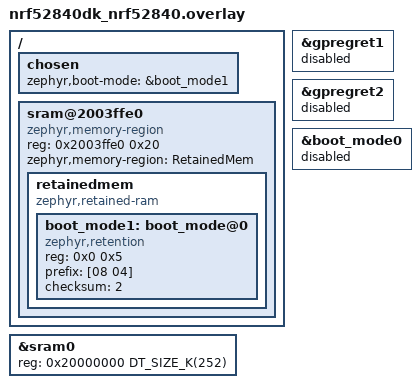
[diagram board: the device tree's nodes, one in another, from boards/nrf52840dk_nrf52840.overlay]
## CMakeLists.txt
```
#
# Copyright (c) 2026 Nordic Semiconductor ASA
#
# SPDX-License-Identifier: Apache-2.0
#

cmake_minimum_required(VERSION 3.28.0)
find_package(Zephyr REQUIRED HINTS $ENV{ZEPHYR_BASE})
project(retention_bootmode)

target_sources(app PRIVATE src/main.c)
```

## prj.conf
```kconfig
CONFIG_RETAINED_MEM=y
CONFIG_RETENTION=y
CONFIG_BOOT_MODE=y
CONFIG_ZTEST=y
CONFIG_REBOOT=y
```

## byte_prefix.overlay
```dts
/*
 * SPDX-FileCopyrightText: Copyright The Zephyr Project Contributors
 * SPDX-License-Identifier: Apache-2.0
 */

/* Boot mode byte behind a 4-byte prefix */
&boot_mode {
	reg = <0x0 0x5>;
	prefix = [ef 69 16 f0];
};
```

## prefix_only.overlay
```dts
/*
 * SPDX-FileCopyrightText: Copyright The Zephyr Project Contributors
 * SPDX-License-Identifier: Apache-2.0
 */

/* Prefix only, no boot mode byte: the prefix is a bootloader magic value */
&boot_mode {
	reg = <0x0 0x4>;
	prefix = [ef 69 16 f0];
};
```

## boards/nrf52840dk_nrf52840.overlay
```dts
/*
 * Copyright (c) 2026 The Zephyr Project Contributors
 *
 * SPDX-License-Identifier: Apache-2.0
 */

/ {
	chosen {
		zephyr,boot-mode = &boot_mode1;
	};

	sram@2003ffe0 {
		compatible = "zephyr,memory-region", "mmio-sram";
		reg = <0x2003ffe0 0x20>;
		ranges = <0x0 0x2003ffe0 0x20>;
		#address-cells = <1>;
		#size-cells = <1>;
		zephyr,memory-region = "RetainedMem";
		status = "okay";

		retainedmem {
			compatible = "zephyr,retained-ram";
			ranges;
			#address-cells = <1>;
			#size-cells = <1>;
			status = "okay";

			boot_mode1: boot_mode@0 {
				compatible = "zephyr,retention";
				reg = <0x0 0x5>;
				prefix = [08 04];
				checksum = <2>;
				status = "okay";
			};
		};
	};
};

&gpregret1 {
	status = "disabled";
};

&gpregret2 {
	status = "disabled";
};

&sram0 {
	reg = <0x20000000 DT_SIZE_K(252)>;
};

&boot_mode0 {
	status = "disabled";
};
```

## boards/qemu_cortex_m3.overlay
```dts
/*
 * Copyright (c) 2026 The Zephyr Project Contributors
 *
 * SPDX-License-Identifier: Apache-2.0
 */

#include <common/mem.h>

/ {
	chosen {
		zephyr,boot-mode = &boot_mode0;
	};

	sram@2000ffe0 {
		compatible = "zephyr,memory-region", "mmio-sram";
		reg = <0x2000ffe0 0x20>;
		ranges = <0x0 0x2000ffe0 0x20>;
		#address-cells = <1>;
		#size-cells = <1>;
		zephyr,memory-region = "Retention";
		status = "okay";

		retainedmem0: retainedmem {
			compatible = "zephyr,retained-ram";
			ranges;
			#address-cells = <1>;
			#size-cells = <1>;
			status = "okay";

			boot_mode0: boot_mode@0 {
				compatible = "zephyr,retention";
				reg = <0x0 0x5>;
				prefix = [08 04];
				checksum = <2>;
				status = "okay";
			};
		};
	};
};

&sram0 {
	reg = <0x20000000 DT_SIZE_K(60)>;
};
```

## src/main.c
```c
/*
 * Copyright (c) 2026, Nordic Semiconductor ASA
 *
 * SPDX-License-Identifier: Apache-2.0
 */
#include <zephyr/cache.h>
#include <zephyr/drivers/retained_mem.h>
#include <zephyr/bootmode.h>
#include <zephyr/ztest.h>
#include <errno.h>
#include <zephyr/sys/reboot.h>

const static struct device *retained_memory_device = DEVICE_DT_GET(DT_PARENT(DT_CHOSEN(
									zephyr_boot_mode)));

#define TEST_STATUS_NORMAL 0x0
#define TEST_STATUS_REBOOT1 0x184be001
#define TEST_STATUS_REBOOT2 0x391b
#define BOOTMODE_NORMAL 0x0
#define BOOTMODE_VALUE1 0x14
#define BOOTMODE_VALUE2 0xf1
volatile uint32_t test_status __attribute__((section(".noinit.test")));

ZTEST(retention_bootmode_reboot, test_bootmode)
{
	int32_t rc;

	if (test_status == TEST_STATUS_REBOOT1) {
		test_status = BOOTMODE_VALUE2;
		sys_cache_data_flush_range((void *)(uintptr_t)&test_status, sizeof(test_status));

		rc = bootmode_check(BOOTMODE_VALUE1);
		zassert_equal(rc, 1, "Boot mode should be set to test value 1: %d", rc);

		rc = bootmode_check(BOOTMODE_VALUE2);
		zassert_equal(rc, 0, "Boot mode should not be set to test value 2: %d", rc);

		rc = bootmode_check(BOOTMODE_NORMAL);
		zassert_equal(rc, 0, "Boot mode should not be set to default value: %d", rc);

		rc = bootmode_set(BOOTMODE_VALUE2);
		zassert_equal(rc, 0, "Boot mode set should work: %d", rc);

		test_status = TEST_STATUS_REBOOT2;
		sys_cache_data_flush_range((void *)(uintptr_t)&test_status, sizeof(test_status));

		sys_reboot(SYS_REBOOT_COLD);
	} else if (test_status == TEST_STATUS_REBOOT2) {
		test_status = BOOTMODE_NORMAL;
		sys_cache_data_flush_range((void *)(uintptr_t)&test_status, sizeof(test_status));

		rc = bootmode_check(BOOTMODE_VALUE1);
		zassert_equal(rc, 0, "Boot mode should not be set to test value 1: %d", rc);

		rc = bootmode_check(BOOTMODE_VALUE2);
		zassert_equal(rc, 1, "Boot mode should be set to test value 2: %d", rc);

		rc = bootmode_check(BOOTMODE_NORMAL);
		zassert_equal(rc, 0, "Boot mode should not be set to default value: %d", rc);

		/*
		 * Use retained memory directly to ensure checksum and prefix is cleared after test
		 */
		rc = retained_mem_clear(retained_memory_device);
		zassert_equal(rc, 0, "Return code should be success: %d", rc);
	} else {
		rc = bootmode_check(BOOTMODE_VALUE1);
		zassert_equal(rc, 0, "Boot mode should not be set to test value 1: %d", rc);

		rc = bootmode_check(BOOTMODE_VALUE2);
		zassert_equal(rc, 0, "Boot mode should not be set to test value 2: %d", rc);

		rc = bootmode_set(BOOTMODE_VALUE1);
		zassert_equal(rc, 0, "Boot mode set should work: %d", rc);

		test_status = TEST_STATUS_REBOOT1;
		sys_cache_data_flush_range((void *)(uintptr_t)&test_status, sizeof(test_status));

		sys_reboot(SYS_REBOOT_COLD);
	}
}

ZTEST_SUITE(retention_bootmode_reboot, NULL, NULL, NULL, NULL, NULL);
```
